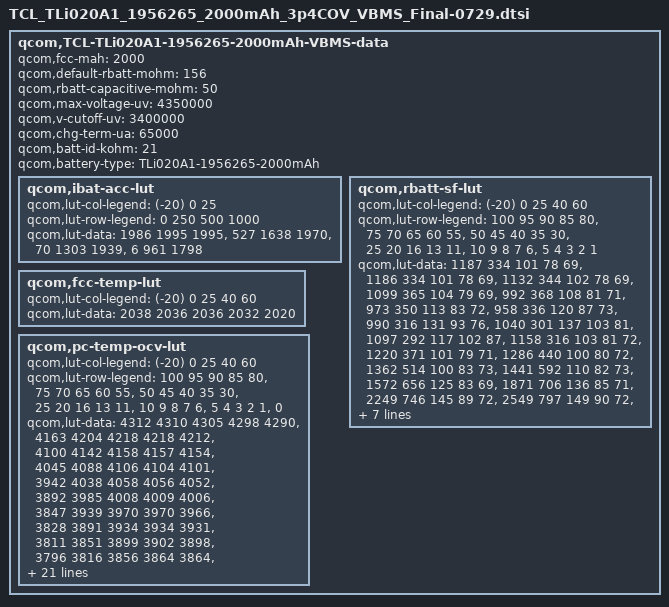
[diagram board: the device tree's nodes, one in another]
 qcom,TCL-TLi020A1-1956265-2000mAh-VBMS-data {
	qcom,fcc-mah = <2000>;
	qcom,default-rbatt-mohm = <156>;
	qcom,rbatt-capacitive-mohm = <50>;
	qcom,max-voltage-uv = <4350000>;
	qcom,v-cutoff-uv = <3400000>;
	qcom,chg-term-ua = <65000>;
	qcom,batt-id-kohm = <21>;
	qcom,battery-type = "TLi020A1-1956265-2000mAh";

	qcom,ibat-acc-lut {
		qcom,lut-col-legend = <(-20) 0 25>;
		qcom,lut-row-legend = <0 250 500 1000>;
		qcom,lut-data = <1986 1995 1995>,
				<527 1638 1970>,
				<70 1303 1939>,
				<6 961 1798>;
	};

	qcom,rbatt-sf-lut {
		qcom,lut-col-legend = <(-20) 0 25 40 60>;
		qcom,lut-row-legend = <100 95 90 85 80>,
				<75 70 65 60 55>,
				<50 45 40 35 30>,
				<25 20 16 13 11>,
				<10 9 8 7 6>,
				<5 4 3 2 1>;
		qcom,lut-data = <1187 334 101 78 69>,
				<1186 334 101 78 69>,
				<1132 344 102 78 69>,
				<1099 365 104 79 69>,
				<992 368 108 81 71>,
				<973 350 113 83 72>,
				<958 336 120 87 73>,
				<990 316 131 93 76>,
				<1040 301 137 103 81>,
				<1097 292 117 102 87>,
				<1158 316 103 81 72>,
				<1220 371 101 79 71>,
				<1286 440 100 80 72>,
				<1362 514 100 83 73>,
				<1441 592 110 82 73>,
				<1572 656 125 83 69>,
				<1871 706 136 85 71>,
				<2249 746 145 89 72>,
				<2549 797 149 90 72>,
				<2540 819 147 91 72>,
				<2797 848 154 92 73>,
				<3171 883 162 95 74>,
				<3720 924 172 97 75>,
				<4165 965 185 101 77>,
				<4960 1009 201 106 79>,
				<5999 1054 217 109 78>,
				<7788 1119 231 112 79>,
				<10682 1239 262 121 85>,
				<15759 1727 315 140 99>,
				<31518 3454 629 200 129>;
	};

	qcom,fcc-temp-lut {
		qcom,lut-col-legend = <(-20) 0 25 40 60>;
		qcom,lut-data = <2038 2036 2036 2032 2020>;
	};

	qcom,pc-temp-ocv-lut {
		qcom,lut-col-legend = <(-20) 0 25 40 60>;
		qcom,lut-row-legend = <100 95 90 85 80>,
				<75 70 65 60 55>,
				<50 45 40 35 30>,
				<25 20 16 13 11>,
				<10 9 8 7 6>,
				<5 4 3 2 1>,
				<0>;
		qcom,lut-data = <4312 4310 4305 4298 4290>,
				<4163 4204 4218 4218 4212>,
				<4100 4142 4158 4157 4154>,
				<4045 4088 4106 4104 4101>,
				<3942 4038 4058 4056 4052>,
				<3892 3985 4008 4009 4006>,
				<3847 3939 3970 3970 3966>,
				<3828 3891 3934 3934 3931>,
				<3811 3851 3899 3902 3898>,
				<3796 3816 3856 3864 3864>,
				<3780 3800 3822 3824 3822>,
				<3764 3792 3800 3802 3801>,
				<3750 3784 3785 3786 3785>,
				<3738 3774 3774 3775 3773>,
				<3724 3762 3768 3764 3760>,
				<3710 3743 3760 3752 3738>,
				<3692 3716 3738 3732 3718>,
				<3672 3694 3710 3706 3694>,
				<3652 3686 3684 3679 3668>,
				<3634 3681 3675 3671 3661>,
				<3620 3678 3673 3669 3659>,
				<3607 3674 3671 3667 3658>,
				<3594 3670 3668 3665 3655>,
				<3573 3663 3665 3662 3652>,
				<3551 3650 3658 3654 3644>,
				<3523 3628 3640 3634 3618>,
				<3490 3592 3597 3588 3571>,
				<3442 3538 3535 3525 3508>,
				<3364 3446 3445 3440 3424>,
				<3236 3307 3314 3310 3292>,
				<3000 3000 3000 3000 3000>;
	};
};
